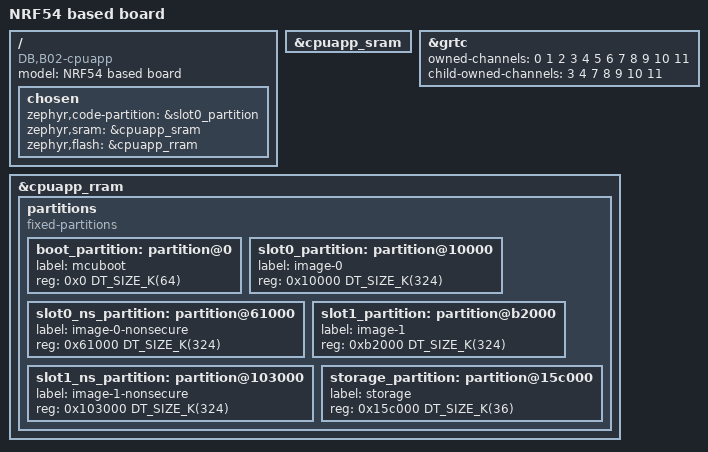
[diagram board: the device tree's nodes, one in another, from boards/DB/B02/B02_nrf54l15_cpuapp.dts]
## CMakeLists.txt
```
cmake_minimum_required(VERSION 3.20.0)
find_package(Zephyr REQUIRED HINTS $ENV{ZEPHYR_BASE})

project(olympus)

target_include_directories(app PRIVATE ${CMAKE_CURRENT_SOURCE_DIR}/common)
add_subdirectory(components/ringbuffer)
add_subdirectory(components/stepCounter)
add_subdirectory(components/accelerometer)
add_subdirectory(components/LED)
add_subdirectory(components/PPG)
add_subdirectory(components/BLE)
add_subdirectory(components/boost)
add_subdirectory(components/heartrate)
target_sources(app PRIVATE src/main.cpp)
```

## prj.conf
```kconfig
CONFIG_SHELL=n
CONFIG_LOG=y
CONFIG_LOG_BACKEND_UART=y
CONFIG_LOG_BACKEND_RTT=y
# 0 = OFF, 1 = ERROR, 2 = WARNING, 3 = INFO, 4 = DEBUG
CONFIG_LOG_DEFAULT_LEVEL=3 
CONFIG_LOG_MODE_DEFERRED=y

#not sure if this does anything but will set to n just in case
CONFIG_FPROTECT=n

CONFIG_GPIO=y

CONFIG_STATIC_INIT_GNU=y

CONFIG_I2C=y

CONFIG_CBPRINTF_FP_SUPPORT=y

CONFIG_LED=y

# Stops from printing *** Booting nRF Connect SDK v3.1.1-e2a97fe2578a ***
CONFIG_NCS_BOOT_BANNER=y
CONFIG_BOOT_BANNER=y

# Redirect standard Printk/Printf
CONFIG_PRINTK=y
CONFIG_RTT_CONSOLE=y
CONFIG_UART_CONSOLE=n

# Essential SEGGER RTT Config
CONFIG_USE_SEGGER_RTT=y
CONFIG_BT_L2CAP_TX_MTU=247
CONFIG_BT_BUF_ACL_RX_SIZE=251
CONFIG_BT_BUF_ACL_TX_SIZE=251
```

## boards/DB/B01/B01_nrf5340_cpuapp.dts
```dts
/dts-v1/;
#include <nordic/nrf5340_cpuapp_qkaa.dtsi>
#include "B01-pinctrl.dtsi"

/ {
	model = "first iteration of the fitness tracker pcb (CPUAPP)";
	compatible = "DB,B01-cpuapp";

	chosen {
		zephyr,sram = &sram0_image;
		zephyr,flash = &flash0;
		zephyr,code-partition = &slot0_partition;
		zephyr,sram-secure-partition = &sram0_s;
		zephyr,sram-non-secure-partition = &sram0_ns;
	};
};

#include "B01-cpuapp_partitioning.dtsi"
#include "B01-shared_sram.dtsi"
```

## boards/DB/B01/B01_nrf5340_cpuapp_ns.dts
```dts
/dts-v1/;
#include <nordic/nrf5340_cpuappns_qkaa.dtsi>
#include "B01-pinctrl.dtsi"

/ {
	model = "first iteration of the fitness tracker pcb (CPUAPP Non-Secure)";
	compatible = "DB,B01-cpuapp-ns";

	chosen {
		zephyr,sram = &sram0_ns;
		zephyr,flash = &flash0;
		zephyr,code-partition = &slot0_ns_partition;
	};
};

#include "B01-cpuapp_partitioning.dtsi"
#include "B01-shared_sram.dtsi"
```

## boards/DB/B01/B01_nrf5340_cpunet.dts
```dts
/dts-v1/;
#include <nordic/nrf5340_cpunet_qkaa.dtsi>
#include "B01-pinctrl.dtsi"

/ {
	model = "first iteration of the fitness tracker pcb";
	compatible = "DB,B01-cpunet";

	chosen {
		zephyr,sram = &sram1;
		zephyr,flash = &flash1;
		zephyr,code-partition = &slot0_partition;
	};
};

&flash1 {
	partitions {
		compatible = "fixed-partitions";
		#address-cells = <1>;
		#size-cells = <1>;

		boot_partition: partition@0 {
			label = "mcuboot";
			reg = <0x00000000 DT_SIZE_K(48)>;
		};

		slot0_partition: partition@c000 {
			label = "image-0";
			reg = <0x0000c000 DT_SIZE_K(92)>;
		};

		slot1_partition: partition@23000 {
			label = "image-1";
			reg = <0x00023000 DT_SIZE_K(92)>;
		};

		storage_partition: partition@3a000 {
			label = "storage";
			reg = <0x0003a000 DT_SIZE_K(24)>;
		};
	};
};

#include "B01-shared_sram.dtsi"
```

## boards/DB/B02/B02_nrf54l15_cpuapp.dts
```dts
/dts-v1/;
#include <nordic/nrf54l15_cpuapp.dtsi>
#include "B02-pinctrl.dtsi"

/ {
	model = "NRF54 based board";
	compatible = "DB,B02-cpuapp";

	chosen {
		zephyr,code-partition = &slot0_partition;
		zephyr,sram = &cpuapp_sram;
		zephyr,flash = &cpuapp_rram;
	};
};

&cpuapp_sram {
	status = "okay";
};

&grtc {
	owned-channels = <0 1 2 3 4 5 6 7 8 9 10 11>;
	/* Channels 7-11 reserved for Zero Latency IRQs, 3-4 for FLPR */
	child-owned-channels = <3 4 7 8 9 10 11>;
	status = "okay";
};

&cpuapp_rram {
	partitions {
		compatible = "fixed-partitions";
		#address-cells = <1>;
		#size-cells = <1>;
		boot_partition: partition@0 {
			label = "mcuboot";
			reg = <0x0 DT_SIZE_K(64)>;
		};
		slot0_partition: partition@10000 {
			label = "image-0";
			reg = <0x10000 DT_SIZE_K(324)>;
		};
		slot0_ns_partition: partition@61000 {
			label = "image-0-nonsecure";
			reg = <0x61000 DT_SIZE_K(324)>;
		};
		slot1_partition: partition@b2000 {
			label = "image-1";
			reg = <0xb2000 DT_SIZE_K(324)>;
		};
		slot1_ns_partition: partition@103000 {
			label = "image-1-nonsecure";
			reg = <0x103000 DT_SIZE_K(324)>;
		};
		/* 32k from 0x154000 to 0x15bfff reserved for TF-M partitions */
		storage_partition: partition@15c000 {
			label = "storage";
			reg = <0x15c000 DT_SIZE_K(36)>;
		};
	};
};
```

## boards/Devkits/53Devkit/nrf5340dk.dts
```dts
&pinctrl {
    i2c1_default: i2c1_default {
        group1 {
            psels = <NRF_PSEL(TWIM_SDA, 0, 7)>,
                    <NRF_PSEL(TWIM_SCL, 0, 6)>;
        };
    };

    i2c1_sleep: i2c1_sleep {
        group1 {
            psels = <NRF_PSEL(TWIM_SDA, 0, 7)>,
                    <NRF_PSEL(TWIM_SCL, 0, 6)>;
            low-power-enable;
        };
    };
};
```

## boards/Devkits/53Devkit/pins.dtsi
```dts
&pinctrl{
    
};
```

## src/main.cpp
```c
/*
* File: main.cpp
* Author: Daniel Bishara
* Date: October 14, 2025
* Description: main entry point for the application. App implementation should be done in the Implementation class
*/

#include <zephyr/kernel.h>
#include <zephyr/logging/log.h>
#include "accelerometer.h"
#include "LED.h"
#include "PPG.h"
#include "BLE.h"
#include "stepCounter.h"

LOG_MODULE_REGISTER( main, CONFIG_LOG_DEFAULT_LEVEL );

int main(void)
{
    StepCounter::Instance().init();
    ImuManager::Instance().init();
    PpgManager::Instance().init();
    BLEManager::Instance().init();
    DebugLEDManager::Instance().init();
    while(1)
    {
        DebugLEDManager::Instance().toggle();
        k_msleep(2000);
    }

    return 0;
}
```
